# H5 register map
Vendor: Allwinner; Series: H5; File version: 0.1
CPU: 0, little endian, MPU, no FPU, 0 interrupt priority bits
Registers are 32-bit, read-write, reset 0x0 unless marked. A register's access mark holds for its fields unless they carry their own. Offsets are from the block's base; [hi:lo] are bit positions; {n}, {i} and the like mark numbered series; 'fields as' and 'values as' point back to an identical list.

## PIO
Base 0x01C20800
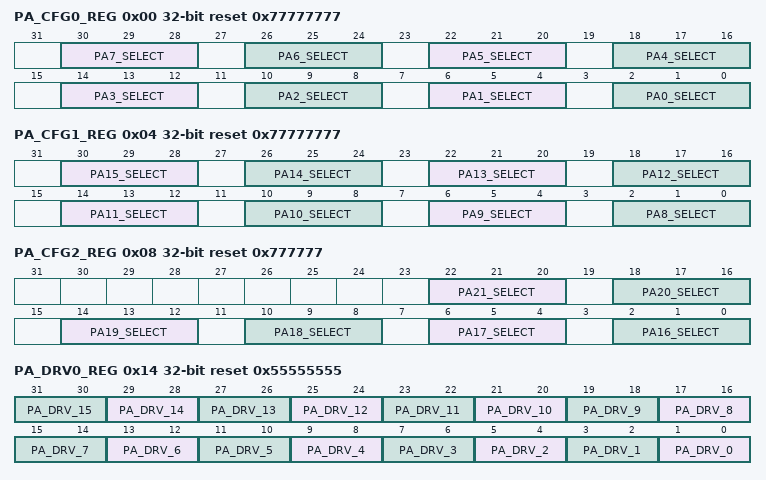
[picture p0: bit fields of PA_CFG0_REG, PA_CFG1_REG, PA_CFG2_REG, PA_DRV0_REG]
0x00 PA_CFG0_REG reset 0x77777777
  [30:28] PA7_SELECT — 000:Input 001:Output 010:SIM0_CLK 011:Reserved 100:Reserved 101:Reserved 110:PA_EINT7 111:IO Disable
  [26:24] PA6_SELECT — 000:Input 001:Output 010:SIM0_PWREN 011:PCM0_MCLK 100:Reserved 101:Reserved 110:PA_EINT6 111:IO Disable
  [22:20] PA5_SELECT — 000:Input 001:Output 010:UART0_RX 011:PWM0 100:Reserved 101:Reserved 110:PA_EINT5 111:IO Disable
  [18:16] PA4_SELECT — 000:Input 001:Output 010:UART0_TX 011:Reserved 100:Reserved 101:Reserved 110:PA_EINT4 111:IO Disable
  [14:12] PA3_SELECT — 000:Input 001:Output 010:UART2_CTS 011:JTAG_DI 100:Reserved 101:Reserved 110:PA_EINT3 111:IO Disable
  [10:8] PA2_SELECT — 000:Input 001:Output 010:UART2_RTS 011:JTAG_DO 100:Reserved 101:Reserved 110:PA_EINT2 111:IO Disable
  [6:4] PA1_SELECT — 000:Input 001:Output 010:UART2_RX 011:JTAG_CK 100:Reserved 101:Reserved 110:PA_EINT1 111:IO Disable
  [2:0] PA0_SELECT — 000:Input 001:Output 010:UART2_TX 011:JTAG_MS 100:Reserved 101:Reserved 110:PA_EINT0 111:IO Disable
0x04 PA_CFG1_REG reset 0x77777777
  [30:28] PA15_SELECT — 000:Input 001:Output 010:SPI1_MOSI 011:UART3_RTS 100:Reserved 101:Reserved 110:PA_EINT15 111:IO Disable
  [26:24] PA14_SELECT — 000:Input 001:Output 010:SPI1_CLK 011:UART3_RX 100:Reserved 101:Reserved 110:PA_EINT14 111:IO Disable
  [22:20] PA13_SELECT — 000:Input 001:Output 010:SPI1_CS 011:UART3_TX 100:Reserved 101:Reserved 110:PA_EINT13 111:IO Disable
  [18:16] PA12_SELECT — 000:Input 001:Output 010:TWI0_SDA 011:DI_RX 100:Reserved 101:Reserved 110:PA_EINT12 111:IO Disable
  [14:12] PA11_SELECT — 000:Input 001:Output 010:TWI0_SCK 011:DI_TX 100:Reserved 101:Reserved 110:PA_EINT11 111:IO Disable
  [10:8] PA10_SELECT — 000:Input 001:Output 010:SIM0_DET 011:Reserved 100:Reserved 101:Reserved 110:PA_EINT10 111:IO Disable
  [6:4] PA9_SELECT — 000:Input 001:Output 010:SIM0_RST 011:Reserved 100:Reserved 101:Reserved 110:PA_EINT9 111:IO Disable
  [2:0] PA8_SELECT — 000:Input 001:Output 010:SIM0_DATA 011:Reserved 100:Reserved 101:Reserved 110:PA_EINT8 111:IO Disable
0x08 PA_CFG2_REG reset 0x777777
  [22:20] PA21_SELECT — 000:Input 001:Output 010:PCM0_DIN 011:SIM0_VPPPP 100:Reserved 101:Reserved 110:PA_EINT21 111:IO Disable
  [18:16] PA20_SELECT — 000:Input 001:Output 010:PCM0_DOUT 011:SIM0_VPPEN 100:Reserved 101:Reserved 110:PA_EINT20 111:IO Disable
  [14:12] PA19_SELECT — 000:Input 001:Output 010:PCM0_CLK 011:TWI1_SDA 100:Reserved 101:Reserved 110:PA_EINT19 111:IO Disable
  [10:8] PA18_SELECT — 000:Input 001:Output 010:PCM0_SYNC 011:TWI1_SCK 100:Reserved 101:Reserved 110:PA_EINT18 111:IO Disable
  [6:4] PA17_SELECT — 000:Input 001:Output 010:OWA_OUT 011:Reserved 100:Reserved 101:Reserved 110:PA_EINT17 111:IO Disable
  [2:0] PA16_SELECT — 000:Input 001:Output 010:SPI1_MISO 011:UART3_CTS 100:Reserved 101:Reserved 110:PA_EINT16 111:IO Disable
0x0C PA_CFG3_REG reset not defined
0x10 PA_DATA_REG
  [21:0] PA_DAT — If the port is configured as input, the corresponding bit is the pin state. If the port is configured as output, the pin state is the same as the corresponding bit. The read bit value is the value setup by software. If the port is configured as functional pin, the undefined value will be read.
0x14 PA_DRV0_REG reset 0x55555555
  [2n+1:2n] PA_DRV_{n} (n=0..15) — PA[n] Multi-Driving Select (n = 0~15) 00: Level 0 01: Level 1 10: Level 2 11: Level 3
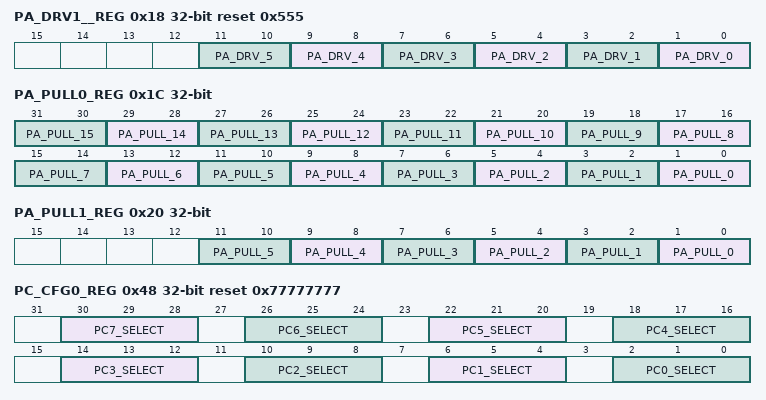
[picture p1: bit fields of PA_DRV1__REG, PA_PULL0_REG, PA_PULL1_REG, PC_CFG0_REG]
0x18 PA_DRV1__REG reset 0x555
  [2n+1:2n] PA_DRV_{n} (n=0..5) — PA[n] Multi-Driving Select (n = 16~21)00: Level 0 01: Level 1 10: Level 2 11: Level 3
0x1C PA_PULL0_REG
  [2n+1:2n] PA_PULL_{n} (n=0..15) — PA[n] Pull-up/down Select (n = 0~15) 00: Pull-up/down disable 01: Pull-up 10: Pull-down 11: Reserved
0x20 PA_PULL1_REG
  [2n+1:2n] PA_PULL_{n} (n=0..5) — PA[n] Pull-up/down Select (n = 16~21) 00: Pull-up/down disable 01: Pull-up 10: Pull-down 11: Reserved
0x48 PC_CFG0_REG reset 0x77777777
  [30:28] PC7_SELECT — 000:Input 001:Output 010:NAND_RB1 011:Reserved 100:Reserved 101:Reserved 110:Reserved 111:IO Disable
  [26:24] PC6_SELECT — 000:Input 001:Output 010:NAND_RB0 011:SDC2_CMD 100:Reserved 101:Reserved 110:Reserved 111:IO Disable
  [22:20] PC5_SELECT — 000:Input 001:Output 010:NAND_RE 011:SDC2_CLK 100:Reserved 101:Reserved 110:Reserved 111:IO Disable
  [18:16] PC4_SELECT — 000:Input 001:Output 010:NAND_CE0 011:Reserved 100:SPI0_MISO 101:Reserved 110:Reserved 111:IO Disable
  [14:12] PC3_SELECT — 000:Input 001:Output 010:NAND_CE1 011:SPI0_CS 100:Reserved 101:Reserved 110:Reserved 111:IO Disable
  [10:8] PC2_SELECT — 000:Input 001:Output 010:NAND_CLE 011:SPI0_CLK 100:Reserved 101:Reserved 110:Reserved 111:IO Disable
  [6:4] PC1_SELECT — 000:Input 001:Output 010:NAND_ALE 011:SPI0_MISO 100:SDC2_DS 101:Reserved 110:Reserved 111:IO Disable
  [2:0] PC0_SELECT — 000:Input 001:Output 010:NAND_WE 011:SPI0_MOSI 100:Reserved 101:Reserved 110:Reserved 111:IO Disable
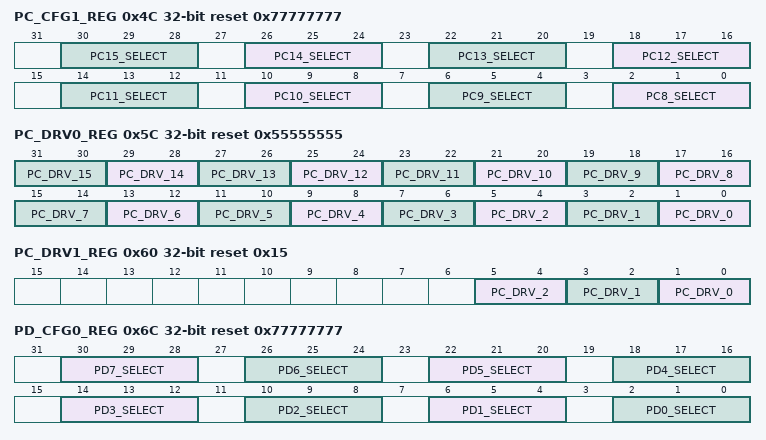
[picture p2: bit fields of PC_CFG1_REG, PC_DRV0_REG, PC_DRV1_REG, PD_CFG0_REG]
0x4C PC_CFG1_REG reset 0x77777777
  [4n-30:4n-32] PC{n}_SELECT (n=8..15) — 000:Input 001:Output 010:NAND_DQ{n-8} 011:SDC2_D{n-8} 100:Reserved 101:Reserved 110:Reserved 111:IO Disable
0x50 PC_CFG2_REG reset 0x777
  [2:0] PC16_SELECT — 000:Input 001:Output 010:NAND_DQS 011:SDC2_RST 100:Reserved 101:Reserved 110:Reserved 111:IO Disable
0x54 PC_CFG3_REG reset not defined
0x58 PC_DATA_REG
  [18:0] PC_DAT — If the port is configured as input, the corresponding bit is the pin state. If the port is configured as output, the pin state is the same as the corresponding bit. The read bit value is the value setup by software. If the port is configured as functional pin, the undefined value will be read.
0x5C PC_DRV0_REG reset 0x55555555
  [2n+1:2n] PC_DRV_{n} (n=0..15) — PC[n] Multi-Driving SELECT (n = 0~15) 00: Level 0 01: Level 1 10: Level 2 11: Level 3
0x60 PC_DRV1_REG reset 0x15
  [5:4] PC_DRV_2 — PC[n] Multi-Driving Select (n = 16~18) 00: Level 0 01: Level 1 10: Level 2 11: Level 3
  [3:2] PC_DRV_1 — PC[n] Multi-Driving Select (n = 16~18) 00: Level 0 01: Level 1 10: Level 2 11: Level 3
  [1:0] PC_DRV_0 — PC[n] Multi-Driving Select (n = 16~18) 00: Level 0 01: Level 1 10: Level 2 11: Level 3
0x64 PC_PULL0_REG reset not defined
0x68 PC_PULL1_REG reset not defined
0x6C PD_CFG0_REG reset 0x77777777
  [30:28] PD7_SELECT — 000:Input 001:Output 010:RGMII_TXD3/MII_TXD3/RMII_NULL 011:Reserved 100:TS2_D3 101:TS3_CLK 110:Reserved 111:IO Disable
  [26:24] PD6_SELECT — 000:Input 001:Output 010:RGMII_NULL/MII_RXERR/RMII_RXER 011:Reserved 100:TS2_D2 101:Reserved 110:Reserved 111:IO Disable
  [22:20] PD5_SELECT — 000:Input 001:Output 010:RGMII_RXCTL/MII_RXDV/RMII_CRS_DV 011:Reserved 100:TS2_D1 101:Reserved 110:Reserved 111:IO Disable
  [18:16] PD4_SELECT — 000:Input 001:Output 010:RGMII_RXCK/MII_RXCK/RMII_NULL 011:Reserved 100:TS2_D0 101:Reserved 110:Reserved 111:IO Disable
  [14:12] PD3_SELECT — 000:Input 001:Output 010:RGMII_RXD0/MII_RXD0/RMII_RXD0 011:Reserved 100:TS2_DVLD 101:Reserved 110:Reserved 111:IO Disable
  [10:8] PD2_SELECT — 000:Input 001:Output 010:RGMII_RXD1/MII_RXD1/RMII_RXD1 011:Reserved 100:TS2_SYNC 101:Reserved 110:Reserved 111:IO Disable
  [6:4] PD1_SELECT — 000:Input 001:Output 010:RGMII_RXD2/MII_RXD2/RMII_NULL 011:DI_RX 100:TS2_ERR 101:Reserved 110:Reserved 111:IO Disable
  [2:0] PD0_SELECT — 000:Input 001:Output 010:RGMII_RXD3/MII_RXD3/RMII_NULL 011:DI_TX 100:TS2_CLK 101:Reserved 110:Reserved 111:IO Disable
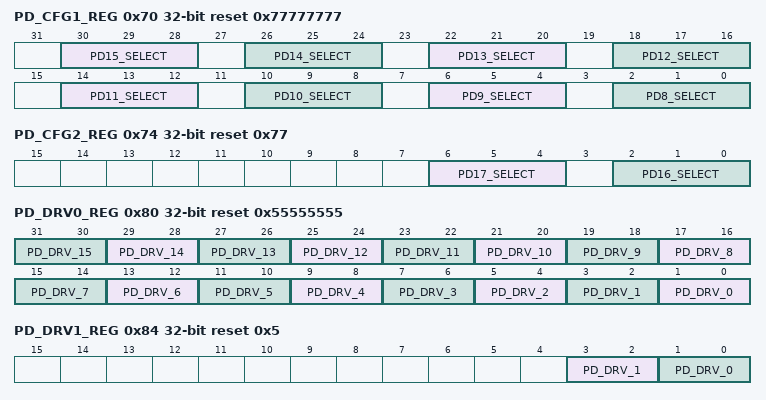
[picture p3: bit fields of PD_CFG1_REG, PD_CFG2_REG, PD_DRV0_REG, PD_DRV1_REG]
0x70 PD_CFG1_REG reset 0x77777777
  [30:28] PD15_SELECT — 000:Input 001:Output 010:RGMII_CLKIN/MII_COL/RMII_NULL 011:Reserved 100:SIM1_RST 101:Reserved 110:Reserved 111:IO Disable
  [26:24] PD14_SELECT — 000:Input 001:Output 010:RGMII_NULL/MII_TXERR/RMII_NULL 011:Reserved 100:SIM1_DATA 101:Reserved 110:Reserved 111:IO Disable
  [22:20] PD13_SELECT — 000:Input 001:Output 010:RGMII_TXCTL/MII_TXEN/RMII_TXEN 011:Reserved 100:SIM1_CLK 101:Reserved 110:Reserved 111:IO Disable
  [18:16] PD12_SELECT — 000:Input 001:Output 010:RGMII_TXCK/MII_TXCK/RMII_TXCK 011:Reserved 100:SIM1_PWREN 101:Reserved 110:Reserved 111:IO Disable
  [14:12] PD11_SELECT — 000:Input 001:Output 010:RGMII_NULL/MII_CRS/RMII_NULL 011:Reserved 100:TS2_D7 101:TS3_D0 110:Reserved 111:IO Disable
  [10:8] PD10_SELECT — 000:Input 001:Output 010:RGMII_TXD0/MII_TXD0/RMII_TXD0 011:Reserved 100:TS2_D6 101:TS3_DVLD 110:Reserved 111:IO Disable
  [6:4] PD9_SELECT — 000:Input 001:Output 010:RGMII_TXD1/MII_TXD1/RMII_TXD1 011:Reserved 100:TS2_D5 101:TS3_SYNC 110:Reserved 111:IO Disable
  [2:0] PD8_SELECT — 000:Input 001:Output 010:RGMII_TXD2/MII_TXD2/RMII_NULL 011:Reserved 100:TS2_D4 101:TS3_ERR 110:Reserved 111:IO Disable
0x74 PD_CFG2_REG reset 0x77
  [6:4] PD17_SELECT — 000:Input 001:Output 010:MDIO 011:Reserved 100:Reserved 101:Reserved 110:Reserved 111:IO Disable
  [2:0] PD16_SELECT — 000:Input 001:Output 010:MDC 011:Reserved 100:SIM1_DET 101:Reserved 110:Reserved 111:IO Disable
0x78 PD_CFG3_REG reset not defined
0x7C PD_DATA_REG
  [17:0] PD_DAT — If the port is configured as input, the corresponding bit is the pin state. If the port is configured as output, the pin state is the same as the corresponding bit. The read bit value is the value setup by software. If the port is configured as functional pin, the undefined value will be read.
0x80 PD_DRV0_REG reset 0x55555555
  [2n+1:2n] PD_DRV_{n} (n=0..15) — PD[n] Multi-Driving SELECT (n = 0~15) 00: Level 0 01: Level 1 10: Level 2 11: Level 3
0x84 PD_DRV1_REG reset 0x5
  [3:2] PD_DRV_1 — PD[n] Multi-Driving Select (n = 16~17) 00: Level 0 01: Level 1 10: Level 2 11: Level 3
  [1:0] PD_DRV_0 — PD[n] Multi-Driving Select (n = 16~17) 00: Level 0 01: Level 1 10: Level 2 11: Level 3
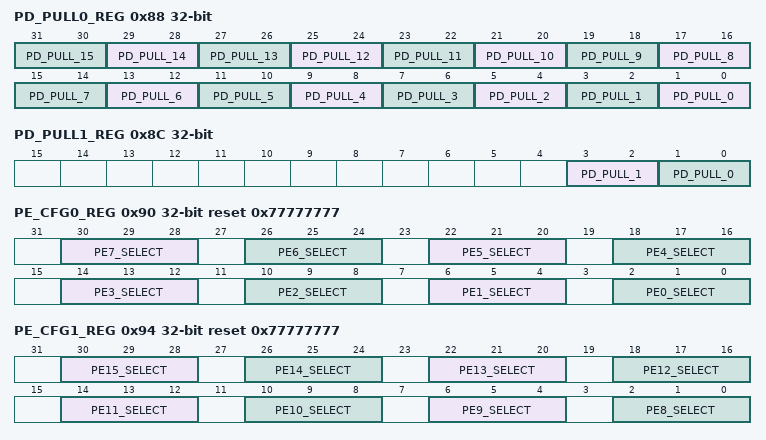
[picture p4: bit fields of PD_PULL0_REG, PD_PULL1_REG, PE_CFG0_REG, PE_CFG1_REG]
0x88 PD_PULL0_REG
  [2n+1:2n] PD_PULL_{n} (n=0..15) — PD[n] Pull-up/down Select (n = 0~15) 00: Pull-up/down disable 01: Pull-up 10: Pull-down 11: Reserved
0x8C PD_PULL1_REG
  [3:2] PD_PULL_1 — PD[n] Pull-up/down Select (n = 16~17) 00: Pull-up/down disable 01: Pull-up 10: Pull-down 11: Reserved
  [1:0] PD_PULL_0 — PD[n] Pull-up/down Select (n = 16~17) 00: Pull-up/down disable 01: Pull-up 10: Pull-down 11: Reserved
0x90 PE_CFG0_REG reset 0x77777777
  [30:28] PE7_SELECT — 000:Input 001:Output 010:CSI_D3 011:TS0_D3 100:TS1_CLK 101:Reserved 110:Reserved 111:IO Disable
  [26:24] PE6_SELECT — 000:Input 001:Output 010:CSI_D2 011:TS0_D2 100:Reserved 101:Reserved 110:Reserved 111:IO Disable
  [22:20] PE5_SELECT — 000:Input 001:Output 010:CSI_D1 011:TS0_D1 100:Reserved 101:Reserved 110:Reserved 111:IO Disable
  [18:16] PE4_SELECT — 000:Input 001:Output 010:CSI_D0 011:TS0_D0 100:Reserved 101:Reserved 110:Reserved 111:IO Disable
  [14:12] PE3_SELECT — 000:Input 001:Output 010:CSI_VSYNC 011:TS0_DVLD 100:Reserved 101:Reserved 110:Reserved 111:IO Disable
  [10:8] PE2_SELECT — 000:Input 001:Output 010:CSI_HSYNC 011:TS0_SYNC 100:Reserved 101:Reserved 110:Reserved 111:IO Disable
  [6:4] PE1_SELECT — 000:Input 001:Output 010:CSI_MCLK 011:TS0_ERR 100:Reserved 101:Reserved 110:Reserved 111:IO Disable
  [2:0] PE0_SELECT — 000:Input 001:Output 010:CSI_PCLK 011:TS0_CLK 100:Reserved 101:Reserved 110:Reserved 111:IO Disable
0x94 PE_CFG1_REG reset 0x77777777
  [30:28] PE15_SELECT — 000:Input 001:Output 010:Reserved 011:SIM1_VPPPP 100:Reserved 101:Reserved 110:Reserved 111:IO Disable
  [26:24] PE14_SELECT — 000:Input 001:Output 010:Reserved 011:SIM1_VPPEN 100:Reserved 101:Reserved 110:Reserved 111:IO Disable
  [22:20] PE13_SELECT — 000:Input 001:Output 010:CSI_SDA 011:TWI2_SDA 100:Reserved 101:Reserved 110:Reserved 111:IO Disable
  [18:16] PE12_SELECT — 000:Input 001:Output 010:CSI_SCK 011:TWI2_SCK 100:Reserved 101:Reserved 110:Reserved 111:IO Disable
  [14:12] PE11_SELECT — 000:Input 001:Output 010:CSI_D7 011:TS0_D7 100:TS1_D0 101:Reserved 110:Reserved 111:IO Disable
  [10:8] PE10_SELECT — 000:Input 001:Output 010:CSI_D6 011:TS0_D6 100:TS1_DVLD 101:Reserved 110:Reserved 111:IO Disable
  [6:4] PE9_SELECT — 000:Input 001:Output 010:CSI_D5 011:TS0_D5 100:TS1_SYNC 101:Reserved 110:Reserved 111:IO Disable
  [2:0] PE8_SELECT — 000:Input 001:Output 010:CSI_D4 011:TS0_D4 100:TS1_ERR 101:Reserved 110:Reserved 111:IO Disable
0x98 PE_CFG2_REG reset not defined
0x9C PE_CFG3_REG reset not defined
0xA0 PE_DATA__REG
  [15:0] PE_DAT — If the port is configured as input, the corresponding bit is the pin state. If the port is configured as output, the pin state is the same as the corresponding bit. The read bit value is the value setup by software. If the port is configured as functional pin, the undefined value will be read.
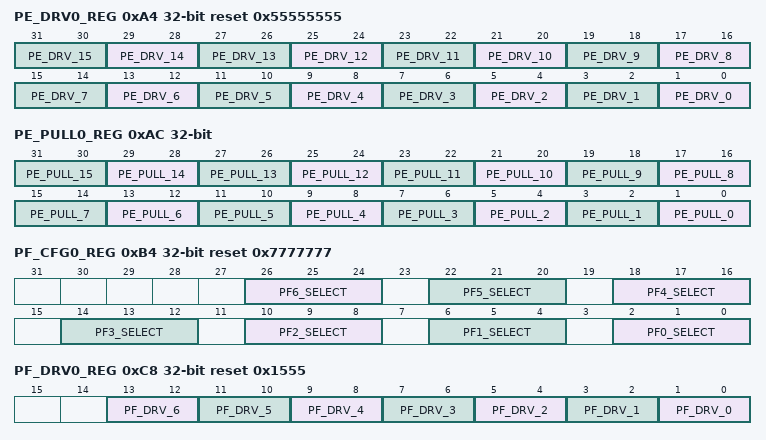
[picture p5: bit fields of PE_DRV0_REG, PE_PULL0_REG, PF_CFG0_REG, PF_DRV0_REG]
0xA4 PE_DRV0_REG reset 0x55555555
  [2n+1:2n] PE_DRV_{n} (n=0..15) — PE[n] Multi-Driving SELECT (n = 0~15) 00: Level 0 01: Level 1 10: Level 2 11: Level 3
0xA8 PE_DRV1_REG reset not defined
0xAC PE_PULL0_REG
  [2n+1:2n] PE_PULL_{n} (n=0..15) — PE[n] Pull-up/down Select (n = 0~15) 00: Pull-up/down disable 01: Pull-up 10: Pull-down 11: Reserved
0xB0 PE_PULL1_REG reset not defined
0xB4 PF_CFG0_REG reset 0x7777777
  [26:24] PF6_SELECT — 000:Input 001:Output 010:Reserved 011:Reserved 100:Reserved 101:Reserved 110:PF_EINT6 111:IO Disable
  [22:20] PF5_SELECT — 000:Input 001:Output 010:SDC0_D2 011:JTAG_CK 100:Reserved 101:Reserved 110:PF_EINT5 111:IO Disable
  [18:16] PF4_SELECT — 000:Input 001:Output 010:SDC0_D3 011:UART0_RX 100:Reserved 101:Reserved 110:PF_EINT4 111:IO Disable
  [14:12] PF3_SELECT — 000:Input 001:Output 010:SDC0_CMD 011:JTAG_DO 100:Reserved 101:Reserved 110:PF_EINT3 111:IO Disable
  [10:8] PF2_SELECT — 000:Input 001:Output 010:SDC0_CLK 011:UART0_TX 100:Reserved 101:Reserved 110:PF_EINT2 111:IO Disable
  [6:4] PF1_SELECT — 000:Input 001:Output 010:SDC0_D0 011:JTAG_DI 100:Reserved 101:Reserved 110:PF_EINT1 111:IO Disable
  [2:0] PF0_SELECT — 000:Input 001:Output 010:SDC0_D1 011:JTAG_MS 100:Reserved 101:Reserved 110:PF_EINT0 111:IO Disable
{0xB4+4i} PF_CFG{i}_REG reset not defined (i=1..3)
0xC4 PF_DATA_REG
  [6:0] PF_DAT — If the port is configured as input, the corresponding bit is the pin state. If the port is configured as output, the pin state is the same as the corresponding bit. The read bit value is the value setup by software. If the port is configured as functional pin, the undefined value will be read.
0xC8 PF_DRV0_REG reset 0x1555
  [2n+1:2n] PF_DRV_{n} (n=0..6) — PF[n] Multi-Driving SELECT (n = 0~6) 00: Level 0 01: Level 1 10: Level 2 11: Level 3
0xCC PF_DRV1_REG reset not defined
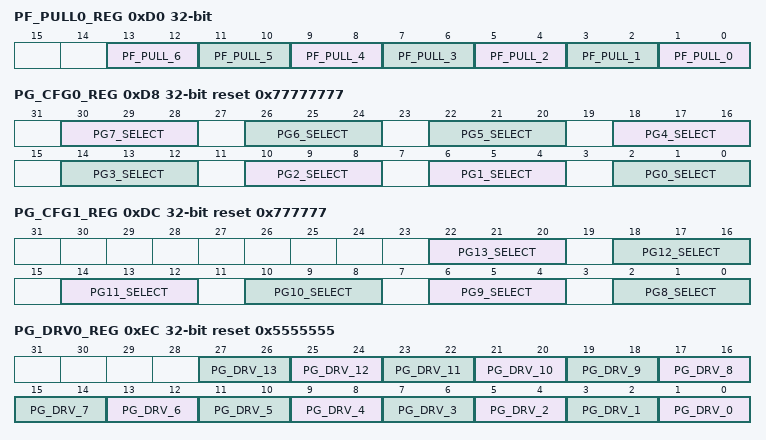
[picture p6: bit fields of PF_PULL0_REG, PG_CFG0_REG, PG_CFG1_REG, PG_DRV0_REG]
0xD0 PF_PULL0_REG
  [2n+1:2n] PF_PULL_{n} (n=0..6) — PF[n] Pull-up/down Select (n = 0~6) 00: Pull-up/down disable 01: Pull-up 10: Pull-down 11: Reserved
0xD4 PF_PULL1_REG reset not defined
0xD8 PG_CFG0_REG reset 0x77777777
  [30:28] PG7_SELECT — 000:Input 001:Output 010:UART1_RX 011: Reserved 100:Reserved 101:Reserved 110:PG_EINT7 111:IO Disable
  [26:24] PG6_SELECT — 000:Input 001:Output 010:UART1_TX 011: Reserved 100:Reserved 101:Reserved 110:PG_EINT6 111:IO Disable
  [4n+2:4n] PG{n}_SELECT (n=2..5) — 000:Input 001:Output 010:SDC1_D{n-2} 011:Reserved 100:Reserved 101:Reserved 110:PG_EINT{n} 111:IO Disable
  [6:4] PG1_SELECT — 000:Input 001:Output 010:SDC1_CMD 011:Reserved 100:Reserved 101:Reserved 110:PG_EINT1 111:IO Disable
  [2:0] PG0_SELECT — 000:Input 001:Output 010:SDC1_CLK 011:Reserved 100:Reserved 101:Reserved 110:PG_EINT0 111:IO Disable
0xDC PG_CFG1_REG reset 0x777777
  [22:20] PG13_SELECT — 000:Input 001:Output 010: PCM1_DIN 011: Reserved 100:Reserved 101:Reserved 110:PG_EINT13 111:IO Disable
    2=PCM1_DIN
  [18:16] PG12_SELECT — 000:Input 001:Output 010: PCM1_DOUT 011: Reserved 100:Reserved 101:Reserved 110:PG_EINT12 111:IO Disable
    2=PCM1_DOUT
  [14:12] PG11_SELECT — 000:Input 001:Output 010: PCM1_CLK 011: Reserved 100:Reserved 101:Reserved 110:PG_EINT11 111:IO Disable
    2=PCM1_CLK
  [10:8] PG10_SELECT — 000:Input 001:Output 010: PCM1_SYNC 011: Reserved 100:Reserved 101:Reserved 110:PG_EINT10 111:IO Disable
    2=PCM1_SYNC
  [6:4] PG9_SELECT — 000:Input 001:Output 010:UART1_CTS 011: Reserved 100:Reserved 101:Reserved 110:PG_EINT9 111:IO Disable
  [2:0] PG8_SELECT — 000:Input 001:Output 010:UART1_RTS 011: Reserved 100:Reserved 101:Reserved 110:PG_EINT8 111:IO Disable
0xE0 PG_CFG2_REG reset not defined
0xE4 PG_CFG3_REG reset not defined
0xE8 PG_DATA_REG
  [13:0] PG_DAT — If the port is configured as input, the corresponding bit is the pin state. If the port is configured as output, the pin state is the same as the corresponding bit. The read bit value is the value setup by software. If the port is configured as functional pin, the undefined value will be read.
0xEC PG_DRV0_REG reset 0x5555555
  [2n+1:2n] PG_DRV_{n} (n=0..13) — PG[n] Multi-Driving SELECT (n = 0~13) 00: Level 0 01: Level 1 10: Level 2 11: Level 3
0xF0 PG_DRV1_REG reset not defined
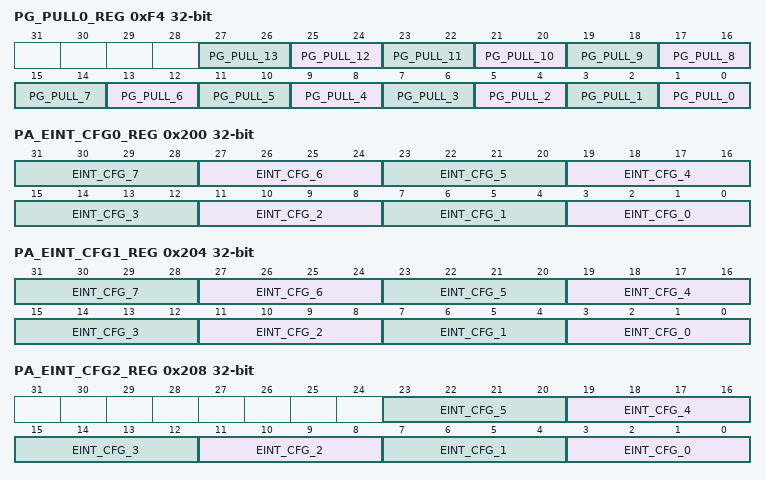
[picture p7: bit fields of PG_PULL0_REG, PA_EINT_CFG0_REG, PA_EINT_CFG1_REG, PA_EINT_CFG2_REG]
0xF4 PG_PULL0_REG
  [2n+1:2n] PG_PULL_{n} (n=0..13) — PG[n] Pull-up/down Select (n = 0~13) 00: Pull-up/down disable 01: Pull-up 10: Pull-down 11: Reserved
0xF8 PG_PULL1_REG reset not defined
0x200 PA_EINT_CFG0_REG
  [4n+3:4n] EINT_CFG_{n} (n=0..7) — External INTn Mode (n = 0~7) 0000: Positive Edge 0001: Negative Edge 0010: High Level 0011: Low Level 0100: Double Edge (Positive/ Negative) Others: Reserved
0x204 PA_EINT_CFG1_REG
  [4n+3:4n] EINT_CFG_{n} (n=0..7) — External INTn Mode (n = 8~15) 0000: Positive Edge 0001: Negative Edge 0010: High Level 0011: Low Level 0100: Double Edge (Positive/ Negative) Others: Reserved
0x208 PA_EINT_CFG2_REG
  [4n+3:4n] EINT_CFG_{n} (n=0..5) — External INTn Mode (n = 16~21) 0000: Positive Edge 0001: Negative Edge 0010: High Level 0011: Low Level 0100: Double Edge (Positive/ Negative) Others: Reserved
0x20C PA_EINT_CFG3_REG reset not defined
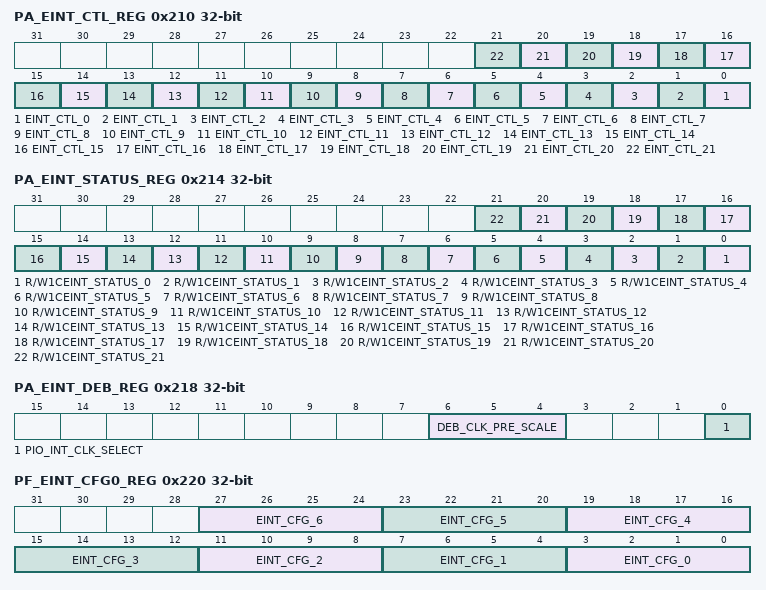
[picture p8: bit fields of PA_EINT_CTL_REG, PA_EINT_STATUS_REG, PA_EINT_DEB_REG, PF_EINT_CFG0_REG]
0x210 PA_EINT_CTL_REG
  [n] EINT_CTL_{n} (n=0..21) — External INTn Enable (n = 0~21) 0: Disable 1: Enable
0x214 PA_EINT_STATUS_REG
  [n] R/W1CEINT_STATUS_{n} (n=0..21) — External INTn Pending Bit (n = 0~21) 0: No IRQ pending 1: IRQ pending W ite to clear it.
0x218 PA_EINT_DEB_REG
  [6:4] DEB_CLK_PRE_SCALE — Debounce Clock Pre-scale n The selected clock source is prescaled by 2^n.
  [0] PIO_INT_CLK_SELECT — PIO Interrupt Clock Select 0: LOSC 32KHz 1: HOSC 24MHz
    0=LOSC (LOSC 32KHz); 1=HOSC (HOSC 24MHz)
0x220 PF_EINT_CFG0_REG
  [4n+3:4n] EINT_CFG_{n} (n=0..6) — External INTn Mode (n = 0~6) 0000: Positive Edge 0001: Negative Edge 0010: High Level 0011: Low Level 0100: Double Edge (Positive/ Negative) Others: Reserved
{0x220+4i} PF_EINT_CFG{i}_REG reset not defined (i=1..3)
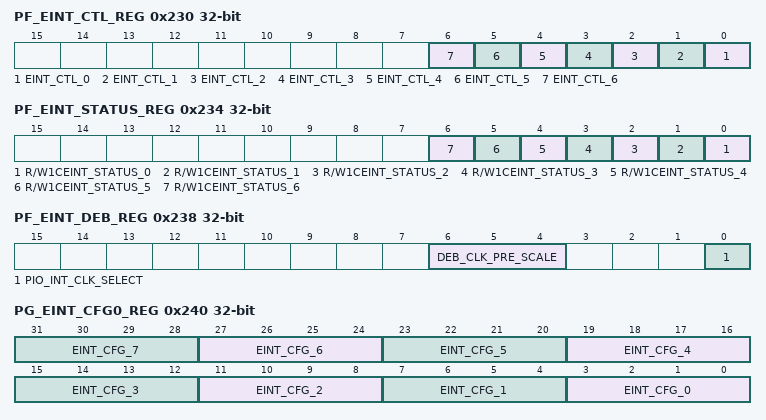
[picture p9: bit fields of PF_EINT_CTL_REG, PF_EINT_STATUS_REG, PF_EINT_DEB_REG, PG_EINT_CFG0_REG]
0x230 PF_EINT_CTL_REG
  [n] EINT_CTL_{n} (n=0..6) — External INTn Enable (n = 0~6) 0: Disable 1: Enable
0x234 PF_EINT_STATUS_REG
  [n] R/W1CEINT_STATUS_{n} (n=0..6) — External INTn Pending Bit (n = 0~6) 0: No IRQ pending 1: IRQ pending W ite to lea it
0x238 PF_EINT_DEB_REG
  fields as PA_EINT_DEB_REG
0x240 PG_EINT_CFG0_REG
  fields as PA_EINT_CFG0_REG
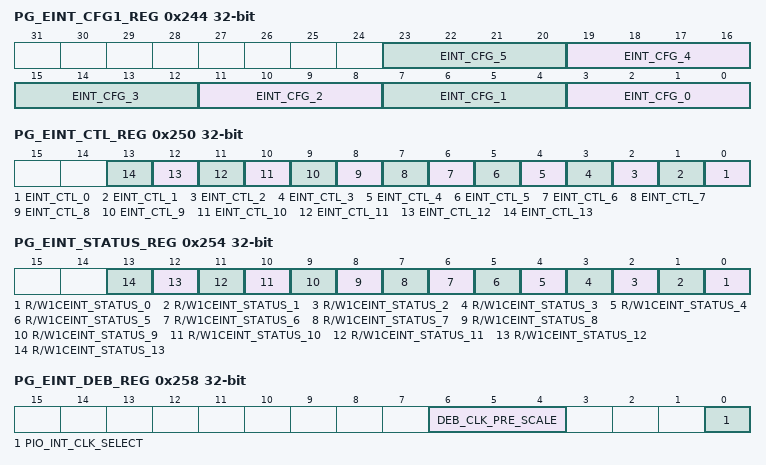
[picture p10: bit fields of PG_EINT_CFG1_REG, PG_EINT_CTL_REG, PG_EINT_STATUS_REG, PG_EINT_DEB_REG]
0x244 PG_EINT_CFG1_REG
  [4n+3:4n] EINT_CFG_{n} (n=0..5) — External INTn Mode (n = 8~13) 0000: Positive Edge 0001: Negative Edge 0010: High Level 0011: Low Level 0100: Double Edge (Positive/ Negative) Others: Reserved
0x248 PG_EINT_CFG2_REG reset not defined
0x24C PG_EINT_CFG3_REG reset not defined
0x250 PG_EINT_CTL_REG
  [n] EINT_CTL_{n} (n=0..13) — External INTn Enable (n = 0~13) 0: Disable 1: Enable
0x254 PG_EINT_STATUS_REG
  [n] R/W1CEINT_STATUS_{n} (n=0..13) — External INTn Pending Bit (n = 0~13) 0: No IRQ pending 1: IRQ pending W ite to lea it
0x258 PG_EINT_DEB_REG
  fields as PA_EINT_DEB_REG
